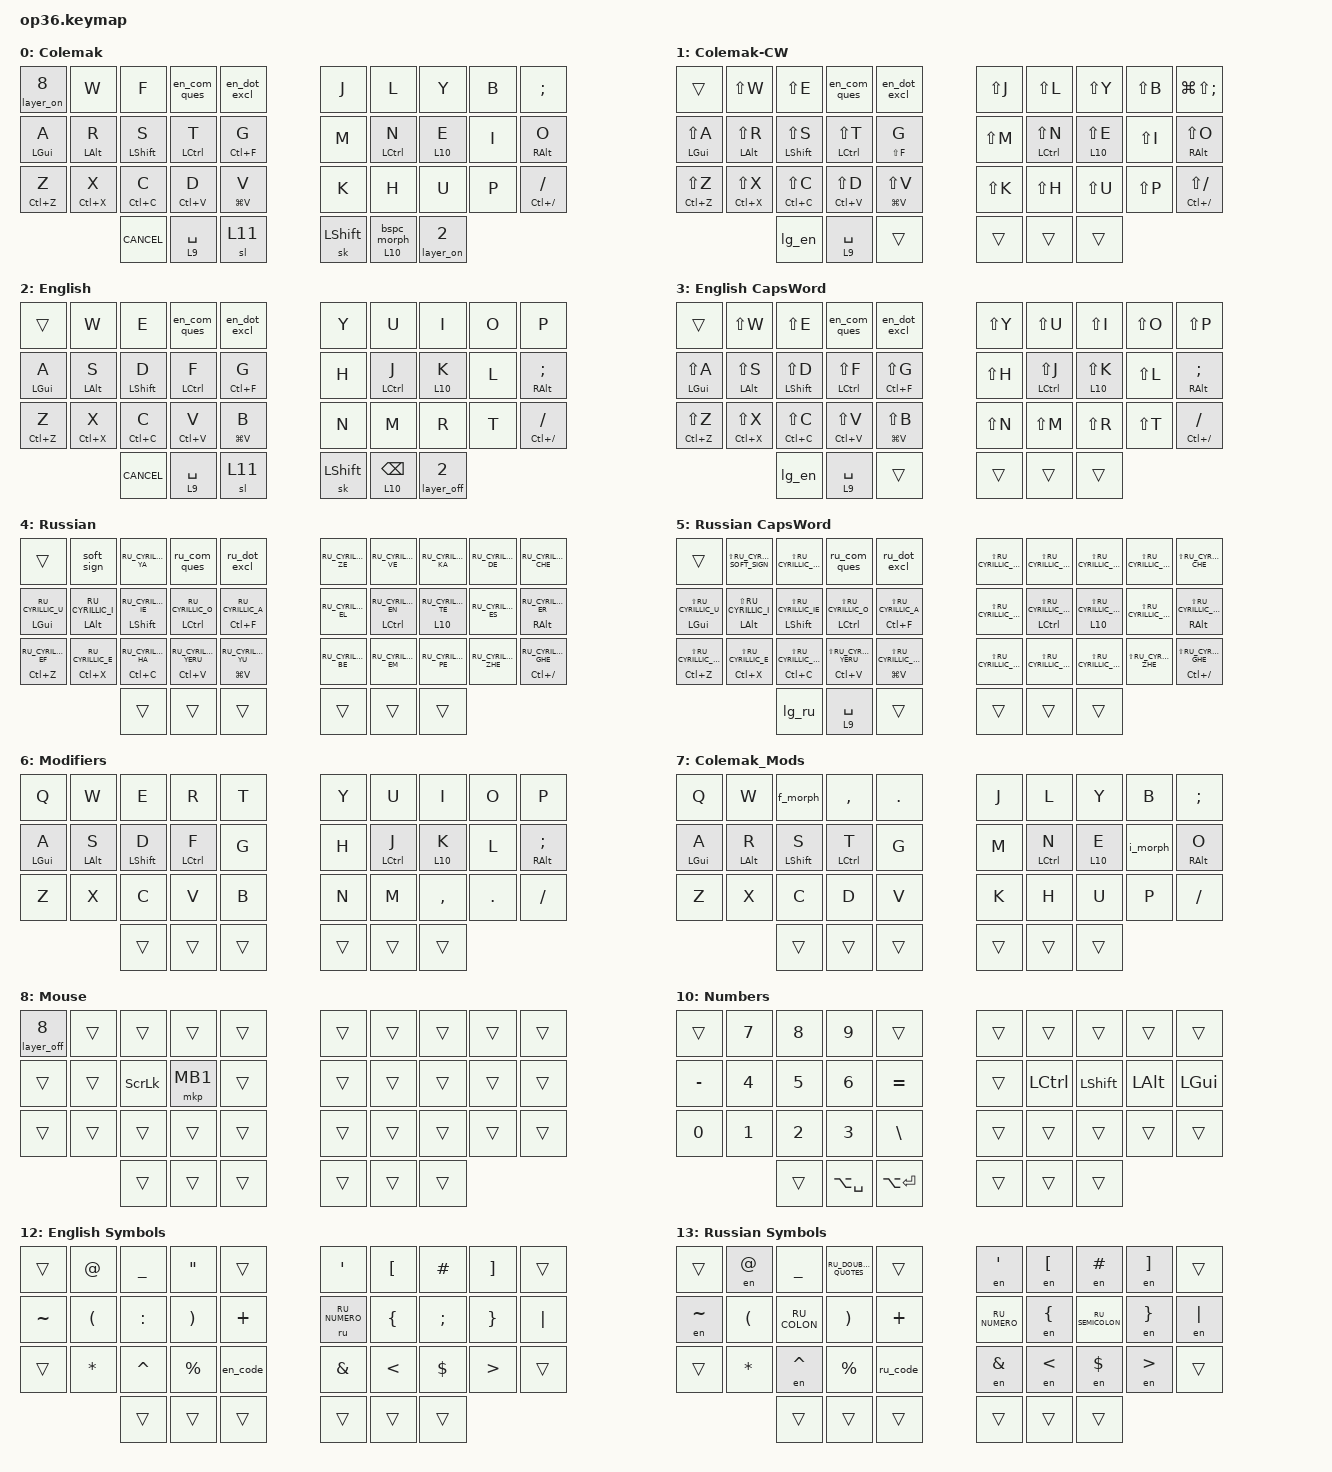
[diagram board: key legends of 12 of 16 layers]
#include "keys_ru.h"
#include <dt-bindings/zmk/behaviors.h>
#include <behaviors.dtsi>
#include <dt-bindings/zmk/bt.h>
#include <dt-bindings/zmk/keys.h>
#include <dt-bindings/zmk/pointing.h>

&mt {
    flavor = "tap-preferred";
    tapping-term-ms = <200>;
};

&lt {
    flavor = "balanced";
    tapping-term-ms = <150>;
};

&caps_word {
    continue-list = <MINUS SEMICOLON UNDERSCORE SINGLE_QUOTE LEFT_BRACKET RIGHT_BRACKET COMMA DOT GRAVE BACKSPACE DELETE>;
    mods = <(MOD_LSFT)>;
};

&sl {
    release-after-ms = <5000>;
    ignore-modifiers;
};

&sk {
    release-after-ms = <5000>;
    quick-release;
};

/ {
    combos {
        compatible = "zmk,combos";

        combo_ctrl_ent {
            bindings = <&kp LC(ENTER)>;
            key-positions = <1 3>;
            require-prior-idle-ms = <50>;
        };

        combo_enter {
            bindings = <&kp ENTER>;
            key-positions = <2 1>;
            require-prior-idle-ms = <50>;
        };

        combo_tab {
            bindings = <&kp TAB>;
            key-positions = <11 12>;
            require-prior-idle-ms = <70>;
            timeout-ms = <25>;
        };

        combo_esc {
            bindings = <&kp ESC>;
            key-positions = <21 22>;
            require-prior-idle-ms = <50>;
        };

        combo_ru {
            bindings = <&lg_ru>;
            key-positions = <22 23>;
            require-prior-idle-ms = <50>;
        };

        combo_en {
            bindings = <&lg_en>;
            key-positions = <26 27>;
            require-prior-idle-ms = <50>;
        };

        combo_osl_sym_en {
            bindings = <&sl 12>;
            key-positions = <16 17>;
            require-prior-idle-ms = <50>;
            layers = <2 3 12 0 1>;
        };

        combo_quotes_en {
            bindings = <&quotes_en>;
            require-prior-idle-ms = <50>;
            key-positions = <26 28>;
            layers = <2 3 0 1>;
        };

        combo_osl_sym_ru {
            bindings = <&sl 13>;
            key-positions = <16 17>;
            require-prior-idle-ms = <50>;
            layers = <5 13 4>;
        };

        combo_quotes_ru {
            bindings = <&quotes_ru>;
            key-positions = <26 28>;
            require-prior-idle-ms = <50>;
            layers = <5 4 13>;
        };

        combo_braces_en {
            bindings = <&braces_en>;
            key-positions = <16 18>;
            require-prior-idle-ms = <50>;
            layers = <2 3 0 1 12>;
        };

        combo_yi_ru {
            bindings = <&kp RU_CYRILLIC_SHORT_I>;
            timeout-ms = <30>;
            key-positions = <17 18>;
            layers = <4>;
        };

        combo_she_ru {
            bindings = <&kp RU_CYRILLIC_SHA>;
            timeout-ms = <30>;
            key-positions = <27 28>;
            layers = <4>;
        };

        combo_scha_ru {
            bindings = <&kp RU_CYRILLIC_SHCHA>;
            timeout-ms = <30>;
            key-positions = <7 8>;
            layers = <4>;
        };

        combo_yi_cw {
            bindings = <&kp LS(RU_CYRILLIC_SHORT_I)>;
            timeout-ms = <30>;
            key-positions = <17 18>;
            layers = <5>;
        };

        combo_she_cw {
            bindings = <&kp LS(RU_CYRILLIC_SHA)>;
            timeout-ms = <30>;
            key-positions = <27 28>;
            layers = <5>;
        };

        combo_scha_cw {
            bindings = <&kp LS(RU_CYRILLIC_SHCHA)>;
            timeout-ms = <30>;
            key-positions = <7 8>;
            layers = <5>;
        };

        combo_capsword_en {
            bindings = <&to 3>;
            key-positions = <11 10>;
            layers = <2 3>;
            timeout-ms = <30>;
        };

        combo_osl_fn {
            bindings = <&sl 14>;
            key-positions = <21 23>;
            require-prior-idle-ms = <50>;
        };

        combo_osl_os {
            bindings = <&sl 15>;
            key-positions = <20 21>;
            require-prior-idle-ms = <50>;
        };

        combo_capsword_ru {
            bindings = <&to 5>;
            key-positions = <11 10>;
            layers = <5 4>;
            timeout-ms = <30>;
        };

        combo_yo_ru {
            bindings = <&kp RU_CYRILLIC_IO>;
            key-positions = <18 19>;
            layers = <4>;
            timeout-ms = <30>;
        };

        combo_yo_cw_ru {
            bindings = <&kp LS(RU_CYRILLIC_IO)>;
            key-positions = <18 19>;
            layers = <5>;
            timeout-ms = <30>;
        };

        combo_yo_en {
            bindings = <&ru RU_CYRILLIC_IO>;
            key-positions = <18 19>;
            layers = <2 0>;
            timeout-ms = <30>;
        };

        combo_q_en {
            bindings = <&kp Q>;
            key-positions = <3 2>;
            layers = <2 0>;
            timeout-ms = <30>;
        };

        combo_p_en {
            bindings = <&kp P>;
            key-positions = <7 6>;
            layers = <2>;
            timeout-ms = <30>;
        };

        combo_q_cw {
            bindings = <&kp LS(Q)>;
            key-positions = <3 2>;
            layers = <3 1>;
            timeout-ms = <30>;
        };

        combo_p_cw {
            bindings = <&kp LS(P)>;
            key-positions = <6 7>;
            layers = <3>;
            timeout-ms = <30>;
        };

        combo_tse_ru {
            bindings = <&kp RU_CYRILLIC_TSE>;
            key-positions = <2 3>;
            layers = <4>;
            timeout-ms = <30>;
        };

        combo_tse_cw {
            bindings = <&kp LS(RU_CYRILLIC_TSE)>;
            key-positions = <2 3>;
            layers = <5>;
            timeout-ms = <30>;
        };

        combo_che_ru {
            bindings = <&kp RU_CYRILLIC_CHE>;
            key-positions = <6 7>;
            layers = <4>;
            timeout-ms = <30>;
        };

        combo_che_cw {
            bindings = <&kp LS(RU_CYRILLIC_CHE)>;
            key-positions = <6 7>;
            layers = <5>;
            timeout-ms = <30>;
        };

        combo_osm_ctrl_shift {
            bindings = <&osm_ctrl_shift>;
            key-positions = <13 14>;
            require-prior-idle-ms = <70>;
            timeout-ms = <25>;
            layers = <2 4 3 5 0 1>;
        };

        parentheses {
            bindings = <&parentheses>;
            key-positions = <11 13>;
            require-prior-idle-ms = <70>;
            timeout-ms = <25>;
        };

        combo_braces_ru {
            bindings = <&braces_ru>;
            key-positions = <16 18>;
            require-prior-idle-ms = <70>;
            timeout-ms = <25>;
            layers = <4 5 13>;
        };

        combo_brackets_en {
            bindings = <&brackets_en>;
            key-positions = <6 8>;
            layers = <2 3 0 1 12>;
            timeout-ms = <30>;
        };

        combo_brackets_ru {
            bindings = <&brackets_ru>;
            key-positions = <6 8>;
            layers = <4 5 13>;
            timeout-ms = <30>;
        };

        combo_osm_ctrl {
            bindings = <&osm_ctrl>;
            key-positions = <12 13>;
            layers = <2 3 0 1 4 5>;
        };

        combo_minus {
            bindings = <&kp MINUS>;
            key-positions = <3 4>;
        };

        combo_grave_ru {
            bindings = <&en GRAVE>;
            key-positions = <15 16>;
            layers = <4 5 13>;
        };

        combo_grave_en {
            bindings = <&kp GRAVE>;
            key-positions = <15 16>;
            layers = <2 3 0 1 12>;
        };

        combo_under_en {
            bindings = <&kp UNDER>;
            key-positions = <6 5>;
            layers = <3 2 0 1 12>;
        };

        combo_under_ru {
            bindings = <&kp UNDER>;
            key-positions = <5 6>;
            layers = <4 5 13>;
        };

        combo_capsword_colemak {
            bindings = <&to 1>;
            key-positions = <10 11>;
            layers = <0 1>;
        };

        combo_ru_hash {
            bindings = <&en HASH>;
            key-positions = <25 26>;
            layers = <4 5 13>;
        };

        combo_en_hash {
            bindings = <&kp HASH>;
            key-positions = <26 25 26>;
            layers = <2 0 1 3 12>;
        };
    };

    macros {
        lg_ru: lg_ru {
            compatible = "zmk,behavior-macro";
            #binding-cells = <0>;
            bindings = <&to 4 &os_ru>;
            label = "LG_RU";
            tap-ms = <0>;
            wait-ms = <0>;
        };

        lg_en: lg_en {
            compatible = "zmk,behavior-macro";
            #binding-cells = <0>;
            bindings = <&to 0 &os_en>;
            label = "LG_EN";
            tap-ms = <0>;
            wait-ms = <0>;
        };

        os_ru: os_ru {
            compatible = "zmk,behavior-macro";
            #binding-cells = <0>;
            bindings =
                <&macro_wait_time 15>,
                <&kp LC(LS(N8))>,
                <&macro_wait_time 15>;

            label = "OS_RU";
            tap-ms = <30>;
        };

        os_en: os_en {
            compatible = "zmk,behavior-macro";
            #binding-cells = <0>;
            bindings =
                <&macro_wait_time 15>,
                <&kp LC(LS(N9))>,
                <&macro_wait_time 15>;

            label = "OS_EN";
            tap-ms = <30>;
        };

        alt_tab: alt_tab {
            compatible = "zmk,behavior-macro";
            #binding-cells = <0>;
            bindings =
                <&macro_press>,
                <&kp LEFT_ALT>,
                <&macro_wait_time 50>,
                <&macro_tap>,
                <&kp TAB>,
                <&macro_wait_time 30>,
                <&macro_release>,
                <&kp LEFT_ALT>;

            label = "ALT_TAB";
            tap-ms = <30>;
        };

        select_row: select_row {
            compatible = "zmk,behavior-macro";
            #binding-cells = <0>;
            bindings = <&kp END &kp LS(HOME)>;
            label = "SELECT_ROW";
        };

        en_code: en_code_block {
            compatible = "zmk,behavior-macro";
            #binding-cells = <0>;
            bindings =
                <&kp GRAVE &kp GRAVE &kp GRAVE>,
                <&macro_wait_time 10>,
                <&kp RETURN &kp RET>,
                <&macro_wait_time 10>,
                <&kp GRAVE &kp GRAVE &kp GRAVE>,
                <&macro_wait_time 10>,
                <&kp UP_ARROW>;

            label = "EN_CODE_BLOCK";
        };

        ru_code: ru_code {
            compatible = "zmk,behavior-macro";
            #binding-cells = <0>;
            bindings =
                <&os_en &kp GRAVE &kp GRAVE &kp GRAVE>,
                <&macro_wait_time 10>,
                <&kp RETURN &kp RET>,
                <&macro_wait_time 10>,
                <&kp GRAVE &kp GRAVE &kp GRAVE>,
                <&macro_wait_time 10>,
                <&kp UP_ARROW &os_ru>;

            label = "RU_CODE";
        };

        ru_cw_off: ru_cw_off {
            compatible = "zmk,behavior-macro-one-param";
            #binding-cells = <1>;
            bindings = <&macro_param_1to1 &kp MACRO_PLACEHOLDER &to 4>;
            label = "RU_CW_OFF";
            wait-ms = <0>;
            tap-ms = <0>;
        };

        en_cw_off: en_cw_off {
            compatible = "zmk,behavior-macro-one-param";
            #binding-cells = <1>;
            bindings = <&macro_param_1to1 &kp MACRO_PLACEHOLDER &to 0>;
            label = "EN_CW_OFF";
            wait-ms = <0>;
            tap-ms = <0>;
        };

        zeros_macro: zeros_macro {
            compatible = "zmk,behavior-macro";
            #binding-cells = <0>;
            bindings = <&kp N0 &kp N0 &kp N0 &kp N0 &kp N0 &kp N0>;
            label = "ZEROS_MACRO";
            tap-ms = <350>;
        };

        osm_ctrl_shift: osm_ctrl_shift {
            compatible = "zmk,behavior-macro";
            #binding-cells = <0>;
            bindings = <&sk LS(LCTRL) &sl 7>;
            label = "OSM_CTRL_SHIFT";
            wait-ms = <0>;
            tap-ms = <0>;
        };

        ml: ml {
            compatible = "zmk,behavior-macro-one-param";
            #binding-cells = <1>;
            bindings =
                <&macro_param_1to1 &key_on MACRO_PLACEHOLDER &layer_on 7>,
                <&macro_pause_for_release>,
                <&macro_param_1to1 &key_off MACRO_PLACEHOLDER &layer_off 7>;

            label = "Mod Layer";
            wait-ms = <0>;
            tap-ms = <0>;
        };

        quotes_ru: dbl_quote {
            compatible = "zmk,behavior-macro";
            #binding-cells = <0>;
            bindings = <&kp LS(NUMBER_2) &kp LS(NUMBER_2) &kp LEFT_ARROW>;
            label = "DBL_QUOTE";
        };

        quotes_en: quotes_en {
            compatible = "zmk,behavior-macro";
            #binding-cells = <0>;
            bindings = <&kp DOUBLE_QUOTES &kp DOUBLE_QUOTES &kp LEFT_ARROW>;
            label = "QUOTES_EN";
        };

        braces_en: braces_en {
            compatible = "zmk,behavior-macro";
            #binding-cells = <0>;
            bindings = <&kp LEFT_BRACE &kp RIGHT_BRACE &kp LEFT>;
            label = "BRACES_EN";
        };

        braces_ru: braces_ru {
            compatible = "zmk,behavior-macro";
            #binding-cells = <0>;
            bindings = <&os_en &braces_en &os_ru>;
            label = "BRACES_RU";
        };

        brackets_en: brackets_en {
            compatible = "zmk,behavior-macro";
            #binding-cells = <0>;
            bindings = <&kp LEFT_BRACKET &kp RIGHT_BRACKET &kp LEFT_ARROW>;
            label = "BRACKETS_EN";
        };

        brackets_ru: brackets_ru {
            compatible = "zmk,behavior-macro";
            #binding-cells = <0>;
            bindings = <&os_en &brackets_en &os_ru>;
            label = "BRACKETS_RU";
        };

        parentheses: parentheses {
            compatible = "zmk,behavior-macro";
            #binding-cells = <0>;
            bindings = <&kp LEFT_PARENTHESIS &kp RIGHT_PARENTHESIS &kp LEFT_ARROW>;
            label = "PARENTHESES";
        };

        less_greater_en: less_greater_en {
            compatible = "zmk,behavior-macro";
            #binding-cells = <0>;
            bindings = <&kp LESS_THAN &kp GREATER_THAN &kp LEFT>;
            label = "LESS_GREATER_EN";
        };

        less_greater_ru: less_greater_ru {
            compatible = "zmk,behavior-macro";
            #binding-cells = <0>;
            bindings = <&os_en &less_greater_en &os_ru>;
            label = "LESS_GREATER_RU";
        };

        en: en {
            compatible = "zmk,behavior-macro-one-param";
            #binding-cells = <1>;
            bindings = <&os_en &macro_param_1to1 &kp MACRO_PLACEHOLDER &os_ru>;
            label = "EN";
        };

        ru: ru {
            compatible = "zmk,behavior-macro-one-param";
            #binding-cells = <1>;
            bindings = <&os_ru &macro_param_1to1 &kp MACRO_PLACEHOLDER &os_en>;
            label = "RU";
        };

        osm_ctrl: osm_ctrl {
            compatible = "zmk,behavior-macro";
            #binding-cells = <0>;
            bindings = <&sk LCTRL &sl 7>;
            label = "OSM_CTRL";
            wait-ms = <0>;
            tap-ms = <0>;
        };

        sync_lg: sync_lg {
            compatible = "zmk,behavior-macro";
            #binding-cells = <0>;
            bindings = <&tog 4>;
            label = "SYNC_LG";
        };
    };

    behaviors {
        layer_off: layer_off {
            compatible = "zmk,behavior-toggle-layer";
            label = "LAYER_OFF";
            #binding-cells = <1>;
            toggle-mode = "off";
        };

        hrm: hrm {
            compatible = "zmk,behavior-hold-tap";
            label = "Home Row Mod";
            bindings = <&kp>, <&kp>;

            #binding-cells = <2>;
            tapping-term-ms = <150>;
            flavor = "balanced";
            require-prior-idle-ms = <20>;
        };

        hrm_slow: hrm_slow {
            compatible = "zmk,behavior-hold-tap";
            label = "HRM for slow fingers";
            bindings = <&kp>, <&kp>;

            #binding-cells = <2>;
            flavor = "tap-preferred";
            tapping-term-ms = <180>;
            require-prior-idle-ms = <20>;
        };

        ru_lt_cw_off: ru_lt_cw_off {
            compatible = "zmk,behavior-hold-tap";
            label = "RU_LT_CW_OFF";
            bindings = <&mo>, <&ru_cw_off>;

            #binding-cells = <2>;
            tapping-term-ms = <180>;
            flavor = "balanced";
        };

        en_lt_cw_off: en_lt_cw_off {
            compatible = "zmk,behavior-hold-tap";
            label = "EN_LT_CW_OFF";
            bindings = <&mo>, <&en_cw_off>;

            #binding-cells = <2>;
            tapping-term-ms = <180>;
            flavor = "balanced";
        };

        hrl: hrl {
            compatible = "zmk,behavior-hold-tap";
            label = "Home Row Layer";
            bindings = <&mo>, <&kp>;

            #binding-cells = <2>;
            tapping-term-ms = <150>;
            flavor = "balanced";
        };

        lt_bspc: lt_bspc {
            compatible = "zmk,behavior-hold-tap";
            label = "LT with quick tap and mod morph";
            bindings = <&mo>, <&bspc_morph>;

            #binding-cells = <2>;
            quick-tap-ms = <180>;
            tapping-term-ms = <180>;
            flavor = "balanced";
        };

        bspc_morph: bspc_morph {
            compatible = "zmk,behavior-mod-morph";
            label = "BSPC_MORPH";
            bindings = <&kp BACKSPACE>, <&kp DELETE>;

            #binding-cells = <0>;
            mods = <(MOD_LALT)>;
        };

        key_on: key_on {
            compatible = "zmk,behavior-key-toggle";
            label = "KEY_ON";
            #binding-cells = <1>;
        };

        key_off: key_off {
            compatible = "zmk,behavior-key-toggle";
            label = "KEY_OFF";
            #binding-cells = <1>;
            toggle-mode = "off";
        };

        hrml: hrml {
            compatible = "zmk,behavior-hold-tap";
            label = "Home Row Mod Layer";
            bindings = <&ml>, <&kp>;

            #binding-cells = <2>;
            tapping-term-ms = <150>;
            flavor = "balanced";
            require-prior-idle-ms = <20>;
        };

        layer_on: layer_on {
            compatible = "zmk,behavior-toggle-layer";
            label = "LAYER_ON";
            #binding-cells = <1>;
            toggle-mode = "on";
        };

        hrml_slow: hrml_slow {
            compatible = "zmk,behavior-hold-tap";
            label = "HRML for slow fingers";
            bindings = <&ml>, <&kp>;

            #binding-cells = <2>;
            tapping-term-ms = <160>;
            flavor = "tap-preferred";
            require-prior-idle-ms = <20>;
        };

        soft_sign: soft_sign {
            compatible = "zmk,behavior-mod-morph";
            label = "SOFT_SIGN";
            bindings = <&kp M>, <&kp RIGHT_BRACKET>;

            #binding-cells = <0>;
            mods = <(MOD_LSFT)>;
        };

        en_dot_excl: en_dot_excl {
            compatible = "zmk,behavior-mod-morph";
            label = "EN_DOT_EXCL";
            bindings = <&en_cw_off DOT>, <&en_cw_off EXCL>;

            #binding-cells = <0>;
            mods = <(MOD_LSFT)>;
        };

        en_com_ques: en_com_ques {
            compatible = "zmk,behavior-mod-morph";
            label = "EN_COM_QUES";
            bindings = <&en_cw_off COMMA>, <&en_cw_off QUESTION>;

            #binding-cells = <0>;
            mods = <(MOD_LSFT)>;
        };

        ru_dot_excl: ru_dot_excl {
            compatible = "zmk,behavior-mod-morph";
            label = "RU_DOT_EXCL";
            bindings = <&ru_cw_off RU_DOT>, <&ru_cw_off EXCL>;

            #binding-cells = <0>;
            mods = <(MOD_LSFT)>;
        };

        ru_com_ques: ru_com_ques {
            compatible = "zmk,behavior-mod-morph";
            label = "RU_COM_QUES";
            bindings = <&ru_cw_off RU_COMMA>, <&ru_cw_off RU_QUESTION>;

            #binding-cells = <0>;
            mods = <(MOD_LSFT)>;
        };

        f_morph: f_morph {
            compatible = "zmk,behavior-mod-morph";
            label = "F_MORPH";
            bindings = <&kp F>, <&kp E>;

            #binding-cells = <0>;
            mods = <(MOD_LCTL)>;
            keep-mods = <(MOD_LCTL)>;
        };

        i_morph: i_morph {
            compatible = "zmk,behavior-mod-morph";
            label = "I_MORPH";
            bindings = <&kp I>, <&kp L>;

            #binding-cells = <0>;
            mods = <(MOD_LCTL)>;
            keep-mods = <(MOD_LCTL)>;
        };
    };

    keymap {
        compatible = "zmk,keymap";

        Colemak {
            bindings = <
  &layer_on 8           &kp W                 &kp F                    &en_com_ques   &en_dot_excl                            &kp J          &kp L          &kp Y      &kp B  &kp SEMI
  &hrm_slow LEFT_GUI A  &hrm_slow LEFT_ALT R  &hrml_slow LEFT_SHIFT S  &hrml LCTRL T  &mt LC(F) G                             &kp M          &hrml LCTRL N  &hrl 10 E  &kp I  &hrml_slow RALT O
  &mt LC(Z) Z           &mt LC(X) X           &mt LC(C) C              &mt LC(V) D    &mt LG(V) V                             &kp K          &kp H          &kp U      &kp P  &mt LC(SLASH) SLASH
                                                                       &kp K_CANCEL   &lt 9 SPACE   &sl 11    &sk LEFT_SHIFT  &lt_bspc 10 0  &layer_on 2
            >;
        };

        Colemak-CW {
            bindings = <
  &trans                     &kp LS(W)                  &kp LS(E)                    &en_com_ques       &en_dot_excl                             &kp LS(J)  &kp LS(L)          &kp LS(Y)      &kp LS(B)  &kp LG(LS(SEMI))
  &hrml_slow LEFT_GUI LS(A)  &hrml_slow LEFT_ALT LS(R)  &hrml_slow LEFT_SHIFT LS(S)  &hrml LCTRL LS(T)  &mt LS(F) G                              &kp LS(M)  &hrml LCTRL LS(N)  &hrl 10 LS(E)  &kp LS(I)  &hrml_slow RALT LS(O)
  &mt LC(Z) LS(Z)            &mt LC(X) LS(X)            &mt LC(C) LS(C)              &mt LC(V) LS(D)    &mt LG(V) LS(V)                          &kp LS(K)  &kp LS(H)          &kp LS(U)      &kp LS(P)  &mt LC(SLASH) LS(SLASH)
                                                                                     &lg_en             &en_lt_cw_off 9 SPACE  &trans    &trans  &trans     &trans
            >;
        };

        En {
            bindings = <
  &trans                 &kp W                  &kp E                    &en_com_ques   &en_dot_excl                            &kp Y                  &kp U          &kp I      &kp O  &kp P
  &hrml_slow LEFT_GUI A  &hrml_slow LEFT_ALT S  &hrml_slow LEFT_SHIFT D  &hrml LCTRL F  &mt LC(F) G                             &kp H                  &hrml LCTRL J  &hrl 10 K  &kp L  &hrml_slow RALT SEMI
  &mt LC(Z) Z            &mt LC(X) X            &mt LC(C) C              &mt LC(V) V    &mt LG(V) B                             &kp N                  &kp M          &kp R      &kp T  &mt LC(SLASH) SLASH
                                                                         &kp K_CANCEL   &lt 9 SPACE   &sl 11    &sk LEFT_SHIFT  &lt_bspc 10 BACKSPACE  &layer_off 2
            >;

            label = "English";
        };

        En_CW {
            label = "English CapsWord  ";
            bindings = <
  &trans                     &kp LS(W)                  &kp LS(E)                    &en_com_ques       &en_dot_excl                             &kp LS(Y)  &kp LS(U)          &kp LS(I)      &kp LS(O)  &kp LS(P)
  &hrml_slow LEFT_GUI LS(A)  &hrml_slow LEFT_ALT LS(S)  &hrml_slow LEFT_SHIFT LS(D)  &hrml LCTRL LS(F)  &mt LC(F) LS(G)                          &kp LS(H)  &hrml LCTRL LS(J)  &hrl 10 LS(K)  &kp LS(L)  &hrml_slow RALT SEMI
  &mt LC(Z) LS(Z)            &mt LC(X) LS(X)            &mt LC(C) LS(C)              &mt LC(V) LS(V)    &mt LG(V) LS(B)                          &kp LS(N)  &kp LS(M)          &kp LS(R)      &kp LS(T)  &mt LC(SLASH) SLASH
                                                                                     &lg_en             &en_lt_cw_off 9 SPACE  &trans    &trans  &trans     &trans
            >;
        };

        Ru {
            bindings = <
  &trans                             &soft_sign                         &kp RU_CYRILLIC_YA                    &ru_com_ques                &ru_dot_excl                                &kp RU_CYRILLIC_ZE  &kp RU_CYRILLIC_VE          &kp RU_CYRILLIC_KA      &kp RU_CYRILLIC_DE   &kp RU_CYRILLIC_CHE
  &hrml_slow LEFT_GUI RU_CYRILLIC_U  &hrml_slow LEFT_ALT RU_CYRILLIC_I  &hrml_slow LEFT_SHIFT RU_CYRILLIC_IE  &hrml LCTRL RU_CYRILLIC_O   &mt LC(F) RU_CYRILLIC_A                     &kp RU_CYRILLIC_EL  &hrml LCTRL RU_CYRILLIC_EN  &hrl 10 RU_CYRILLIC_TE  &kp RU_CYRILLIC_ES   &hrml_slow RALT RU_CYRILLIC_ER
  &mt LC(Z) RU_CYRILLIC_EF           &mt LC(X) RU_CYRILLIC_E            &mt LC(C) RU_CYRILLIC_HA              &mt LC(V) RU_CYRILLIC_YERU  &mt LG(V) RU_CYRILLIC_YU                    &kp RU_CYRILLIC_BE  &kp RU_CYRILLIC_EM          &kp RU_CYRILLIC_PE      &kp RU_CYRILLIC_ZHE  &mt LC(SLASH) RU_CYRILLIC_GHE
                                                                                                              &trans                      &trans                    &trans    &trans  &trans              &trans
            >;

            label = "Russian";
        };

        Ru_CW {
            label = "Russian CapsWord ";
            bindings = <
  &trans                                 &kp LS(RU_CYRILLIC_SOFT_SIGN)          &kp LS(RU_CYRILLIC_YA)                    &ru_com_ques                    &ru_dot_excl                                    &kp LS(RU_CYRILLIC_ZE)  &kp LS(RU_CYRILLIC_VE)          &kp LS(RU_CYRILLIC_KA)      &kp LS(RU_CYRILLIC_DE)   &kp LS(RU_CYRILLIC_CHE)
  &hrml_slow LEFT_GUI LS(RU_CYRILLIC_U)  &hrml_slow LEFT_ALT LS(RU_CYRILLIC_I)  &hrml_slow LEFT_SHIFT LS(RU_CYRILLIC_IE)  &hrml LCTRL LS(RU_CYRILLIC_O)   &mt LC(F) LS(RU_CYRILLIC_A)                     &kp LS(RU_CYRILLIC_EL)  &hrml LCTRL LS(RU_CYRILLIC_EN)  &hrl 10 LS(RU_CYRILLIC_TE)  &kp LS(RU_CYRILLIC_ES)   &hrml_slow RALT LS(RU_CYRILLIC_ER)
  &mt LC(Z) LS(RU_CYRILLIC_EF)           &mt LC(X) LS(RU_CYRILLIC_E)            &mt LC(C) LS(RU_CYRILLIC_HA)              &mt LC(V) LS(RU_CYRILLIC_YERU)  &mt LG(V) LS(RU_CYRILLIC_YU)                    &kp LS(RU_CYRILLIC_BE)  &kp LS(RU_CYRILLIC_EM)          &kp LS(RU_CYRILLIC_PE)      &kp LS(RU_CYRILLIC_ZHE)  &mt LC(SLASH) LS(RU_CYRILLIC_GHE)
                                                                                                                          &lg_ru                          &ru_lt_cw_off 9 SPACE         &trans    &trans  &trans                  &trans
            >;
        };

        Mods {
            bindings = <
  &kp Q             &kp W             &kp E                   &kp R         &kp T                     &kp Y   &kp U         &kp I      &kp O    &kp P
  &hrm_slow LGUI A  &hrm_slow LALT S  &hrm_slow LEFT_SHIFT D  &hrm LCTRL F  &kp G                     &kp H   &hrm LCTRL J  &hrl 10 K  &kp L    &hrm_slow RALT SEMICOLON
  &kp Z             &kp X             &kp C                   &kp V         &kp B                     &kp N   &kp M         &kp COMMA  &kp DOT  &kp SLASH
                                                              &trans        &trans  &trans    &trans  &trans  &trans
            >;

            label = "Modifiers";
        };

        Cmk_Mods {
            label = "Colemak_Mods";
            bindings = <
  &kp Q             &kp W             &f_morph                &kp COMMA     &kp DOT                    &kp J   &kp L         &kp Y      &kp B     &kp SEMI
  &hrm_slow LGUI A  &hrm_slow LALT R  &hrm_slow LEFT_SHIFT S  &hrm LCTRL T  &kp G                      &kp M   &hrm LCTRL N  &hrl 10 E  &i_morph  &hrm_slow RALT O
  &kp Z             &kp X             &kp C                   &kp D         &kp V                      &kp K   &kp H         &kp U      &kp P     &kp SLASH
                                                              &trans        &trans   &trans    &trans  &trans  &trans
            >;
        };

        Mouse {
            bindings = <
  &layer_off 8  &trans  &trans          &trans    &trans                    &trans  &trans  &trans  &trans  &trans
  &trans        &trans  &kp SCROLLLOCK  &mkp MB1  &trans                    &trans  &trans  &trans  &trans  &trans
  &trans        &trans  &trans          &trans    &trans                    &trans  &trans  &trans  &trans  &trans
                                        &trans    &trans  &trans    &trans  &trans  &trans
            >;

            label = "Mouse";
        };

        Nav {
            bindings = <
  &none                           &kp LA(TAB)                      &kp LC(LS(LA(LG(TAB))))  &kp LS(LC(LA(LG(F1))))   &key_repeat                     &none   &kp HOME   &kp UP    &kp END    &kp DELETE
  &hrm LEFT_GUI LC(LEFT_BRACKET)  &hrm LALT LC(RIGHT_BRACKET)      &kp LSHFT                &kp LCTRL                &zeros_macro                    &trans  &kp LEFT   &kp DOWN  &kp RIGHT  &select_row
  &mt LC(Z) LS(LG(LEFT_BRACKET))  &mt LC(X) LS(LG(RIGHT_BRACKET))  &mt LC(C) LS(F6)         &mt LC(V) LS(LC(LA(V)))  &trans                          &trans  &kp PG_UP  &none     &kp PG_DN  &trans
                                                                                            &trans                   &trans        &trans    &trans  &trans  &trans
            >;

            label = "Navigation";
        };

        Num {
            bindings = <
  &trans        &kp NUMBER_7  &kp NUMBER_8  &kp NUMBER_9  &trans                                  &trans  &trans     &trans      &trans        &trans
  &kp MINUS     &kp NUMBER_4  &kp NUMBER_5  &kp NUMBER_6  &kp EQUAL                               &trans  &kp LCTRL  &kp LSHIFT  &kp LEFT_ALT  &kp LEFT_GUI
  &kp NUMBER_0  &kp NUMBER_1  &kp NUMBER_2  &kp NUMBER_3  &kp BACKSLASH                           &trans  &trans     &trans      &trans        &trans
                                            &trans        &kp LA(SPACE)  &kp LA(ENTER)    &trans  &trans  &trans
            >;

            label = "Numbers";
        };

        App {
            bindings = <
  &kp LA(LC(LS(P)))  &kp LS(LA(LC(W)))  &kp LS(LA(LC(E)))  &kp LS(LA(LC(R)))      &kp LS(LA(LC(T)))                    &kp LS(LA(LC(Y)))  &kp LS(LA(LC(U)))  &kp LS(LA(LC(I)))      &kp LS(LA(LC(O)))    &kp LS(LA(LC(P)))
  &kp LS(LA(LC(A)))  &kp LS(LA(LC(S)))  &kp LS(LA(LC(D)))  &kp LS(LA(LC(F)))      &kp LS(LA(LC(G)))                    &kp LS(LA(LC(H)))  &kp LS(LA(LC(J)))  &kp LS(LA(LC(K)))      &kp LS(LA(LC(L)))    &kp LS(LA(LC(SEMICOLON)))
  &kp LS(LC(LA(Z)))  &kp LS(LA(LC(X)))  &kp LS(LA(LC(C)))  &kp LA(LS(LC(LG(V))))  &kp LS(LA(LC(B)))                    &kp LS(LA(LC(N)))  &kp LS(LC(LA(M)))  &kp LS(LA(LC(COMMA)))  &kp LS(LA(LC(DOT)))  &kp LS(LC(LA(SLASH)))
                                                           &trans                 &none              &sl 11    &trans  &trans             &trans
            >;

            label = "Applications";
        };

        En_Sym {
            bindings = <
  &trans     &kp AT                &kp UNDER  &kp DOUBLE_QUOTES      &trans                      &kp SINGLE_QUOTE  &kp LEFT_BRACKET  &kp HASH       &kp RIGHT_BRACKET  &trans
  &kp TILDE  &kp LEFT_PARENTHESIS  &kp COLON  &kp RIGHT_PARENTHESIS  &kp PLUS                    &ru RU_NUMERO     &kp LEFT_BRACE    &kp SEMICOLON  &kp RIGHT_BRACE    &kp PIPE
  &trans     &kp ASTRK             &kp CARET  &kp PERCENT            &en_code                    &kp AMPERSAND     &kp LESS_THAN     &kp DOLLAR     &kp GREATER_THAN   &trans
                                              &trans                 &trans    &trans    &trans  &trans            &trans
            >;

            label = "English Symbols";
        };

        RuSym {
            bindings = <
  &trans     &en AT                &kp UNDER     &kp RU_DOUBLE_QUOTES  &trans                      &en SINGLE_QUOTE  &en LEFT_BRACKET  &en HASH          &en RIGHT_BRACKET  &trans
  &en TILDE  &kp LEFT_PARENTHESIS  &kp RU_COLON  &kp RPAR              &kp PLUS                    &kp RU_NUMERO     &en LEFT_BRACE    &kp RU_SEMICOLON  &en RIGHT_BRACE    &en PIPE
  &trans     &kp ASTERISK          &en CARET     &kp PERCENT           &ru_code                    &en AMPERSAND     &en LESS_THAN     &en DOLLAR        &en GREATER_THAN   &trans
                                                 &trans                &trans    &trans    &trans  &trans            &trans
            >;

            label = "Russian Symbols";
        };

        Fn {
            bindings = <
  &trans   &kp F7  &kp F8  &kp F9  &trans                     &trans  &trans     &trans          &trans    &trans
  &kp F11  &kp F4  &kp F5  &kp F6  &kp F12                    &trans  &kp LCTRL  &kp LEFT_SHIFT  &kp LALT  &kp LEFT_GUI
  &kp F10  &kp F1  &kp F2  &kp F3  &trans                     &trans  &trans     &trans          &trans    &trans
                           &trans  &trans   &trans    &trans  &trans  &trans
            >;

            label = "Function";
        };

        OS {
            bindings = <
  &bt BT_SEL 2  &trans         &kp LA(LC(N2))    &kp LC(LA(NUMBER_3))  &kp LC(LA(NUMBER_4))                    &trans  &studio_unlock  &trans  &trans  &bt BT_CLR
  &bt BT_SEL 0  &kp LC(RIGHT)  &kp K_PLAY_PAUSE  &kp C_VOLUME_UP       &kp C_BRI_UP                            &trans  &trans          &trans  &trans  &soft_off
  &bt BT_SEL 1  &trans         &sync_lg          &kp C_VOL_DN          &kp C_BRI_DN                            &trans  &trans          &trans  &trans  &trans
                                                 &trans                &trans                &trans    &trans  &trans  &trans
            >;

            label = "OS";
        };
    };
};
